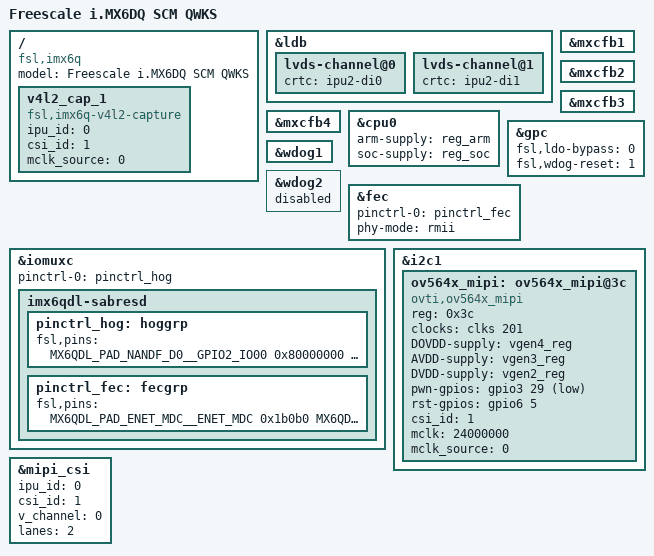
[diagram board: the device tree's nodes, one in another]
/*
 * Copyright 2012 Freescale Semiconductor, Inc.
 * Copyright 2011 Linaro Ltd.
 *
 * The code contained herein is licensed under the GNU General Public
 * License. You may obtain a copy of the GNU General Public License
 * Version 2 or later at the following locations:
 *
 * http://www.opensource.org/licenses/gpl-license.html
 * http://www.gnu.org/copyleft/gpl.html
 */

/dts-v1/;

#include "imx6q.dtsi"
#include "imx6dqscm-qwks-rev2.dtsi"
#include "imx6dqscm-1gb-fix.dtsi"

/ {
	model = "Freescale i.MX6DQ SCM QWKS";
	compatible = "fsl,imx6q";

	v4l2_cap_1 {
		compatible = "fsl,imx6q-v4l2-capture";
		ipu_id = <0>;
		csi_id = <1>;
		mclk_source = <0>;
		status = "okay";
	};

};

&ldb {
	lvds-channel@0 {
		crtc = "ipu2-di0";
	};

	lvds-channel@1 {
		crtc = "ipu2-di1";
	};
};

&mxcfb1 {
	status = "okay";
};

&mxcfb2 {
	status = "okay";
};

&mxcfb3 {
	status = "okay";
};

&mxcfb4 {
	status = "okay";
};

&cpu0 {
	arm-supply = <&reg_arm>;
	soc-supply = <&reg_soc>;
};

&gpc {
	/* use ldo-enable, u-boot will check it and configure */
	fsl,ldo-bypass = <0>;
	/* watchdog select of reset source */
	fsl,wdog-reset = <1>;
};

&wdog1 {
	status = "okay";
};

&wdog2 {
	status = "disabled";
};

&fec {
	pinctrl-names = "default";
	pinctrl-0 = <&pinctrl_fec>;
	phy-mode = "rmii";
	status = "okay";
};

&iomuxc {
	pinctrl-names = "default";
	pinctrl-0 = <&pinctrl_hog>;

	imx6qdl-sabresd {
		pinctrl_hog: hoggrp {
			fsl,pins = <

				MX6QDL_PAD_NANDF_D0__GPIO2_IO00 0x80000000
				MX6QDL_PAD_NANDF_CS1__GPIO6_IO14 0x80000000
				MX6QDL_PAD_NANDF_CS2__GPIO6_IO15 0x80000000
				MX6QDL_PAD_KEY_COL2__GPIO4_IO10 0x80000000
				MX6QDL_PAD_EIM_EB2__GPIO2_IO30 0x80000000
				MX6QDL_PAD_EIM_D22__GPIO3_IO22  0x80000000

				MX6QDL_PAD_GPIO_0__CCM_CLKO1    0x130b0

/*
				MX6QDL_PAD_NANDF_D0__GPIO2_IO00 0x80000000
				MX6QDL_PAD_NANDF_D1__GPIO2_IO01 0x80000000
				//MX6QDL_PAD_GPIO_0__CCM_CLKO1    0x130b0
				MX6QDL_PAD_NANDF_CLE__GPIO6_IO07 0x80000000
				MX6QDL_PAD_NANDF_ALE__GPIO6_IO08 0x80000000
				MX6QDL_PAD_ENET_TXD1__GPIO1_IO29 0x80000000
				MX6QDL_PAD_EIM_D22__GPIO3_IO22  0x80000000
				MX6QDL_PAD_ENET_CRS_DV__GPIO1_IO25 0x80000000
				MX6QDL_PAD_EIM_D26__GPIO3_IO26 0x80000000
				MX6QDL_PAD_EIM_CS1__GPIO2_IO24 0x80000000
				MX6QDL_PAD_ENET_RXD0__GPIO1_IO27 0x80000000
				MX6QDL_PAD_EIM_A25__GPIO5_IO02 0x80000000
				MX6QDL_PAD_EIM_D23__GPIO3_IO23 0x80000000
				MX6QDL_PAD_EIM_EB3__GPIO2_IO31 0x80000000
				MX6QDL_PAD_SD3_RST__GPIO7_IO08	0x80000000
				MX6QDL_PAD_GPIO_9__GPIO1_IO09 	0x80000000
				MX6QDL_PAD_EIM_DA9__GPIO3_IO09 0x80000000
				MX6QDL_PAD_SD1_DAT3__WDOG2_B 0x80000000
				MX6QDL_PAD_NANDF_CS0__GPIO6_IO11 0x80000000
				//MX6QDL_PAD_NANDF_CS1__GPIO6_IO14 0x80000000
				MX6QDL_PAD_NANDF_CS2__GPIO6_IO15 0x80000000
				MX6QDL_PAD_GPIO_4__GPIO1_IO04   0x80000000
				MX6QDL_PAD_GPIO_2__GPIO1_IO02   0x80000000
				MX6QDL_PAD_EIM_EB2__GPIO2_IO30 0x80000000
				MX6QDL_PAD_NANDF_CS0__GPIO6_IO11 0x80000000
				//TOUCH RESET
				MX6QDL_PAD_KEY_COL2__GPIO4_IO10 0x80000000
				//TOUCH_INTERRUPT
				MX6QDL_PAD_NANDF_CS1__GPIO6_IO14 0x80000000

//				//camera
//				MX6QDL_PAD_GPIO_0__GPIO1_IO00  		  0x10881 //0x13059//0x10881
				//MX6QDL_PAD_CSI0_DAT19__GPIO6_IO05       0x80000000//0x17059//0x10881
*/
			>;
		};
		pinctrl_fec: fecgrp {
			fsl,pins = <
				MX6QDL_PAD_ENET_MDC__ENET_MDC		0x1b0b0
				MX6QDL_PAD_ENET_MDIO__ENET_MDIO		0x1b0b0
				MX6QDL_PAD_ENET_CRS_DV__ENET_RX_EN	0x1b0b0
				MX6QDL_PAD_ENET_RX_ER__ENET_RX_ER	0x1b0b0
				MX6QDL_PAD_ENET_TX_EN__ENET_TX_EN	0x1b0b0
				MX6QDL_PAD_ENET_RXD0__ENET_RX_DATA0	0x1b0b0
				MX6QDL_PAD_ENET_RXD1__ENET_RX_DATA1	0x1b0b0
				MX6QDL_PAD_ENET_TXD0__ENET_TX_DATA0	0x1b0b0
				MX6QDL_PAD_ENET_TXD1__ENET_TX_DATA1	0x1b0b0
				MX6QDL_PAD_GPIO_16__ENET_REF_CLK	0x4001b0a8
			>;
		};
	};
};

&i2c1 {
	ov564x_mipi: ov564x_mipi@3c { /* i2c2 driver */
		compatible = "ovti,ov564x_mipi";
		reg = <0x3c>;
		clocks = <&clks 201>;
		clock-names = "csi_mclk";
		DOVDD-supply = <&vgen4_reg>; /* 1.8v */
		AVDD-supply = <&vgen3_reg>;  /* 2.8v, rev C board is VGEN3
						rev B board is VGEN5 */
		DVDD-supply = <&vgen2_reg>;  /* 1.5v*/
		pwn-gpios = <&gpio3 29 1>;   /* active low: EIM_D29 */
		rst-gpios = <&gpio6 5 0>;   /* active high: CSI0_DAT19 */
		csi_id = <1>;
		mclk = <24000000>;
		mclk_source = <0>;
	};
};

&mipi_csi {
	status = "okay";
	ipu_id = <0>;
	csi_id = <1>;
	v_channel = <0>;
	lanes = <2>;
};

